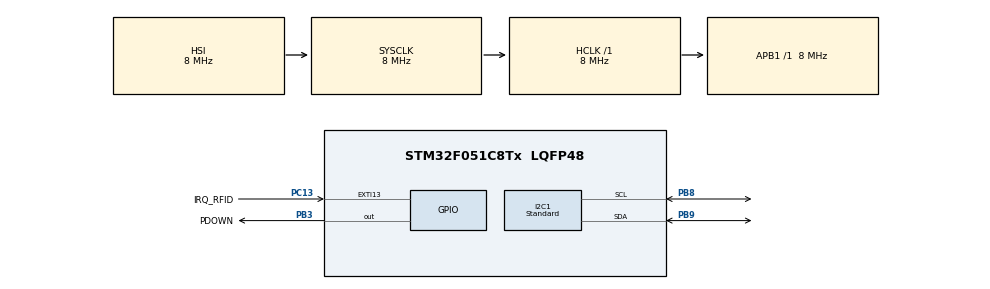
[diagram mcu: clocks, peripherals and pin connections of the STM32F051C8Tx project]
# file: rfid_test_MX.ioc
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I2C1.Analog_Filter=I2C_ANALOGFILTER_DISABLE
I2C1.GeneralCallMode=I2C_GENERALCALL_ENABLE
I2C1.I2C_Fall_Time=0
I2C1.I2C_Rise_Time=0
I2C1.I2C_Speed_Mode=I2C_Standard
I2C1.NoStretchMode=I2C_NOSTRETCH_ENABLE
I2C1.Timing=0x00101D2D
Mcu.Family=STM32F0
Mcu.Name=STM32F051C8Tx
Mcu.Package=LQFP48
NVIC.I2C1_IRQn=true\:0\:0\:false\:false\:true\:true\:true
PA13.Mode=Serial_Wire
PA13.Signal=SYS_SWDIO
PA14.Mode=Serial_Wire
PA14.Signal=SYS_SWCLK
PB3.GPIO_Label=PDOWN
PB3.Signal=GPIO_Output
PB8.Mode=I2C
PB8.Signal=I2C1_SCL
PB9.Mode=I2C
PB9.Signal=I2C1_SDA
PC13.GPIO_Label=IRQ_RFID
PC13.Signal=GPXTI13
ProjectManager.HeapSize=0x200
ProjectManager.StackSize=0x400
ProjectManager.TargetToolchain=Other Toolchains (GPDSC)
RCC.AHBFreq_Value=8000000
RCC.APB1Freq_Value=8000000
RCC.APB1TimFreq_Value=8000000
RCC.HCLKFreq_Value=8000000
RCC.SYSCLKFreq_VALUE=8000000
board=custom

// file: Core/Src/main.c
/* USER CODE BEGIN Header */
/**
  ******************************************************************************
  * @file           : main.c
  * @brief          : Main program body
  ******************************************************************************
  * @attention
  *
  * <h2><center>&copy; Copyright (c) 2021 STMicroelectronics.
  * All rights reserved.</center></h2>
  *
  * This software component is licensed by ST under BSD 3-Clause license,
  * the "License"; You may not use this file except in compliance with the
  * License. You may obtain a copy of the License at:
  *                        opensource.org/licenses/BSD-3-Clause
  *
  ******************************************************************************
  */
/* USER CODE END Header */
#include "main.h"
#include "i2c.h"
#include "gpio.h"

/* USER CODE BEGIN Includes */
#include "main_cpp.h"
/* USER CODE END Includes */

void SystemClock_Config(void);

int main(void)
{

  /* MCU Configuration--------------------------------------------------------*/

  /* Reset of all peripherals, Initializes the Flash interface and the Systick. */
  HAL_Init();

  /* Configure the system clock */
  SystemClock_Config();

  /* Initialize all configured peripherals */
  MX_GPIO_Init();
  MX_I2C1_Init();

  /* Infinite loop */
  /* USER CODE BEGIN WHILE */
  ferroni_loop();
    /* USER CODE END WHILE */

}

void SystemClock_Config(void)
{
  RCC_OscInitTypeDef RCC_OscInitStruct = {0};
  RCC_ClkInitTypeDef RCC_ClkInitStruct = {0};
  RCC_PeriphCLKInitTypeDef PeriphClkInit = {0};

  /** Initializes the RCC Oscillators according to the specified parameters
  * in the RCC_OscInitTypeDef structure.
  */
  RCC_OscInitStruct.OscillatorType = RCC_OSCILLATORTYPE_HSI;
  RCC_OscInitStruct.HSIState = RCC_HSI_ON;
  RCC_OscInitStruct.HSICalibrationValue = RCC_HSICALIBRATION_DEFAULT;
  RCC_OscInitStruct.PLL.PLLState = RCC_PLL_NONE;
  if (HAL_RCC_OscConfig(&RCC_OscInitStruct) != HAL_OK)
  {
    Error_Handler();
  }
  /** Initializes the CPU, AHB and APB buses clocks
  */
  RCC_ClkInitStruct.ClockType = RCC_CLOCKTYPE_HCLK|RCC_CLOCKTYPE_SYSCLK
                              |RCC_CLOCKTYPE_PCLK1;
  RCC_ClkInitStruct.SYSCLKSource = RCC_SYSCLKSOURCE_HSI;
  RCC_ClkInitStruct.AHBCLKDivider = RCC_SYSCLK_DIV1;
  RCC_ClkInitStruct.APB1CLKDivider = RCC_HCLK_DIV1;

  if (HAL_RCC_ClockConfig(&RCC_ClkInitStruct, FLASH_LATENCY_0) != HAL_OK)
  {
    Error_Handler();
  }
  PeriphClkInit.PeriphClockSelection = RCC_PERIPHCLK_I2C1;
  PeriphClkInit.I2c1ClockSelection = RCC_I2C1CLKSOURCE_HSI;
  if (HAL_RCCEx_PeriphCLKConfig(&PeriphClkInit) != HAL_OK)
  {
    Error_Handler();
  }
}

void Error_Handler(void)
{
  __disable_irq();
  while (1)
  {
  }
}

/************************ (C) COPYRIGHT STMicroelectronics *****END OF FILE****/
